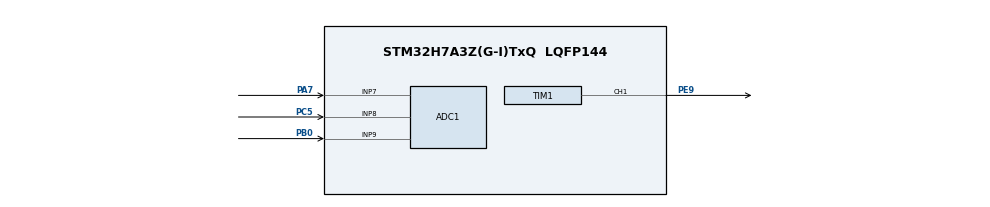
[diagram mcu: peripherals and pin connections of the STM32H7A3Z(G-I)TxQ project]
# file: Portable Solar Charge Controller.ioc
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ADC1.Channel-0\#ChannelRegularConversion=ADC_CHANNEL_7
ADC1.Channel-1\#ChannelRegularConversion=ADC_CHANNEL_8
ADC1.Channel-2\#ChannelRegularConversion=ADC_CHANNEL_9
ADC1.ContinuousConvMode=DISABLE
ADC1.ConversionDataManagement=ADC_CONVERSIONDATA_DMA_ONESHOT
ADC1.EOCSelection=ADC_EOC_SINGLE_CONV
ADC1.NbrOfConversion=3
ADC1.NbrOfConversionFlag=1
ADC1.OffsetNumber-0\#ChannelRegularConversion=ADC_OFFSET_NONE
ADC1.OffsetNumber-1\#ChannelRegularConversion=ADC_OFFSET_NONE
ADC1.OffsetNumber-2\#ChannelRegularConversion=ADC_OFFSET_NONE
ADC1.OffsetSignedSaturation-0\#ChannelRegularConversion=DISABLE
ADC1.OffsetSignedSaturation-1\#ChannelRegularConversion=DISABLE
ADC1.OffsetSignedSaturation-2\#ChannelRegularConversion=DISABLE
ADC1.Rank-0\#ChannelRegularConversion=1
ADC1.Rank-1\#ChannelRegularConversion=2
ADC1.Rank-2\#ChannelRegularConversion=3
ADC1.SamplingTime-0\#ChannelRegularConversion=ADC_SAMPLETIME_1CYCLE_5
ADC1.SamplingTime-1\#ChannelRegularConversion=ADC_SAMPLETIME_1CYCLE_5
ADC1.SamplingTime-2\#ChannelRegularConversion=ADC_SAMPLETIME_1CYCLE_5
ADC1.master=1
CORTEX_M7.default_mode_Activation=1
Dma.ADC1.0.Direction=DMA_PERIPH_TO_MEMORY
Dma.ADC1.0.EventEnable=DISABLE
Dma.ADC1.0.FIFOMode=DMA_FIFOMODE_DISABLE
Dma.ADC1.0.Instance=DMA1_Stream0
Dma.ADC1.0.MemDataAlignment=DMA_MDATAALIGN_HALFWORD
Dma.ADC1.0.MemInc=DMA_MINC_ENABLE
Dma.ADC1.0.Mode=DMA_CIRCULAR
Dma.ADC1.0.PeriphDataAlignment=DMA_PDATAALIGN_HALFWORD
Dma.ADC1.0.PeriphInc=DMA_PINC_DISABLE
Dma.ADC1.0.Polarity=HAL_DMAMUX_REQ_GEN_RISING
Dma.ADC1.0.Priority=DMA_PRIORITY_LOW
Dma.ADC1.0.RequestNumber=1
Dma.ADC1.0.SignalID=NONE
Dma.ADC1.0.SyncEnable=DISABLE
Dma.ADC1.0.SyncPolarity=HAL_DMAMUX_SYNC_NO_EVENT
Dma.ADC1.0.SyncRequestNumber=1
Dma.ADC1.0.SyncSignalID=NONE
Dma.Request0=ADC1
Mcu.Family=STM32H7
Mcu.Name=STM32H7A3Z(G-I)TxQ
Mcu.Package=LQFP144
NUCLEO-H7A3ZI-Q.VCP=true
NVIC.DMA1_Stream0_IRQn=true\:0\:0\:false\:false\:true\:false\:true\:true
NVIC.PriorityGroup=NVIC_PRIORITYGROUP_4
PA7.Signal=ADCx_INP7
PB0.Signal=ADCx_INP9
PC14-OSC32_IN.GPIO_Label=OSC32_IN
PC14-OSC32_IN.Signal=RCC_OSC32_IN
PC15-OSC32_OUT.GPIO_Label=OSC32_OUT
PC15-OSC32_OUT.Signal=RCC_OSC32_OUT
PC5.Signal=ADCx_INP8
PD8.Signal=USART3_TX
PD9.Signal=USART3_RX
PE9.Signal=S_TIM1_CH1
PH0-OSC_IN.GPIO_Label=PH0-MCU
PH0-OSC_IN.Signal=RCC_OSC_IN
PH1-OSC_OUT.GPIO_Label=PH1-MCU
PH1-OSC_OUT.Signal=RCC_OSC_OUT
ProjectManager.HeapSize=0x200
ProjectManager.StackSize=0x400
ProjectManager.TargetToolchain=STM32CubeIDE
RCC.ADCFreq_Value=43000000
RCC.APB1Freq_Value=72000000
RCC.APB2Freq_Value=72000000
RCC.APB3Freq_Value=72000000
RCC.APB4Freq_Value=72000000
RCC.CortexFreq_Value=72000000
RCC.DIVM1=4
RCC.DIVM3=1
RCC.DIVN1=9
RCC.DIVN3=24
RCC.DIVP2=6
RCC.DIVQ1=4
RCC.HCLKFreq_Value=72000000
RCC.HSE_VALUE=8000000
RCC.PLLFRACN=0
RCC.PWR_Regulator_Voltage_Scale=PWR_REGULATOR_VOLTAGE_SCALE0
RCC.SYSCLKFreq_VALUE=72000000
RCC.SYSCLKSource=RCC_SYSCLKSOURCE_PLLCLK
RCC.SupplySource=PWR_DIRECT_SMPS_SUPPLY
RCC.USBCLockSelection=RCC_USBCLKSOURCE_HSI48
RCC.USBFreq_Value=48000000
SH.ADCx_INP7.0=ADC1_INP7,IN7-Single-Ended
SH.ADCx_INP8.0=ADC1_INP8,IN8-Single-Ended
SH.ADCx_INP9.0=ADC1_INP9,IN9-Single-Ended
SH.S_TIM1_CH1.0=TIM1_CH1,PWM Generation1 CH1
TIM1.Channel-PWM\ Generation1\ CH1=TIM_CHANNEL_1
VP_MEMORYMAP_VS_MEMORYMAP.Mode=CurAppReg
VP_NUCLEO-H7A3ZI-Q_VS_BSP_COMMON.Mode=COMMON
VP_TIM1_VS_ClockSourceINT.Mode=Internal
board=NUCLEO-H7A3ZI-Q

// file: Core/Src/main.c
/* USER CODE BEGIN Header */
/**
  ******************************************************************************
  * @file           : main.c
  * @brief          : Main program body
  ******************************************************************************
  * @attention
  *
  * Copyright (c) 2025 STMicroelectronics.
  * All rights reserved.
  *
  * This software is licensed under terms that can be found in the LICENSE file
  * in the root directory of this software component.
  * If no LICENSE file comes with this software, it is provided AS-IS.
  *
  ******************************************************************************
  */
/* USER CODE END Header */
#include "main.h"

#include"Solar_Operations.h"

COM_InitTypeDef BspCOMInit;
//ADC_HandleTypeDef hadc1;
DMA_HandleTypeDef hdma_adc1;

static void MPU_Config(void);

static void MX_DMA_Init(void);

int main(void)
{

  /* MPU Configuration--------------------------------------------------------*/
  MPU_Config();

  /* MCU Configuration--------------------------------------------------------*/

  /* Reset of all peripherals, Initializes the Flash interface and the Systick. */
  HAL_Init();

  /* Configure the system clock */
  SystemClock_Config();

  /* Initialize all configured peripherals */
  MX_GPIO_Init();
  MX_DMA_Init();
  MX_TIM1_Init();
  MX_ADC1_Init();

  /* Initialize COM1 port (115200, 8 bits (7-bit data + 1 stop bit), no parity */
  BspCOMInit.BaudRate   = 115200;
  BspCOMInit.WordLength = COM_WORDLENGTH_8B;
  BspCOMInit.StopBits   = COM_STOPBITS_1;
  BspCOMInit.Parity     = COM_PARITY_NONE;
  BspCOMInit.HwFlowCtl  = COM_HWCONTROL_NONE;
  if (BSP_COM_Init(COM1, &BspCOMInit) != BSP_ERROR_NONE)
  {
    Error_Handler();
  }

  /* Infinite loop */
  /* USER CODE BEGIN WHILE */
  set_duty_cycle(42);

  while (1)
  {
	get_inputs();
	if(scaled_SV>1){
		increment_duty_cycle();
	}
	else{
		decrement_duty_cycle();
	}
	 HAL_Delay(100);
    /* USER CODE END WHILE */

  }
}

static void MX_DMA_Init(void)
{

  /* DMA controller clock enable */
  __HAL_RCC_DMA1_CLK_ENABLE();

  /* DMA interrupt init */
  /* DMA1_Stream0_IRQn interrupt configuration */
  HAL_NVIC_SetPriority(DMA1_Stream0_IRQn, 0, 0);
  HAL_NVIC_EnableIRQ(DMA1_Stream0_IRQn);

}

 /* MPU Configuration */

void MPU_Config(void)
{
  MPU_Region_InitTypeDef MPU_InitStruct = {0};

  /* Disables the MPU */
  HAL_MPU_Disable();

  /** Initializes and configures the Region and the memory to be protected
  */
  MPU_InitStruct.Enable = MPU_REGION_ENABLE;
  MPU_InitStruct.Number = MPU_REGION_NUMBER0;
  MPU_InitStruct.BaseAddress = 0x0;
  MPU_InitStruct.Size = MPU_REGION_SIZE_4GB;
  MPU_InitStruct.SubRegionDisable = 0x87;
  MPU_InitStruct.TypeExtField = MPU_TEX_LEVEL0;
  MPU_InitStruct.AccessPermission = MPU_REGION_NO_ACCESS;
  MPU_InitStruct.DisableExec = MPU_INSTRUCTION_ACCESS_DISABLE;
  MPU_InitStruct.IsShareable = MPU_ACCESS_SHAREABLE;
  MPU_InitStruct.IsCacheable = MPU_ACCESS_NOT_CACHEABLE;
  MPU_InitStruct.IsBufferable = MPU_ACCESS_NOT_BUFFERABLE;

  HAL_MPU_ConfigRegion(&MPU_InitStruct);
  /* Enables the MPU */
  HAL_MPU_Enable(MPU_PRIVILEGED_DEFAULT);

}

void Error_Handler(void)
{
  /* USER CODE BEGIN Error_Handler_Debug */
//  /* User can add his own implementation to report the HAL error return state */
//  __disable_irq();
//  while (1)
//  {
//  }
  /* USER CODE END Error_Handler_Debug */
}
